# trng_reva register map
Registers are read-only, no defined reset value unless marked. A register's access mark holds for its fields unless they carry their own. Offsets are from the block's base; lines under a group give offsets from that group; [hi:lo] are bit positions; {n}, {i} and the like mark numbered series; 'fields as' and 'values as' point back to an identical list; <NAME> marks a mode.

## Memory map
0x400B5000 TRNG size 0x1000 — Random Number Generator.

## Interrupts
4 TRNG — TRNG interrupt.

## TRNG — Random Number Generator.
Base 0x400B5000
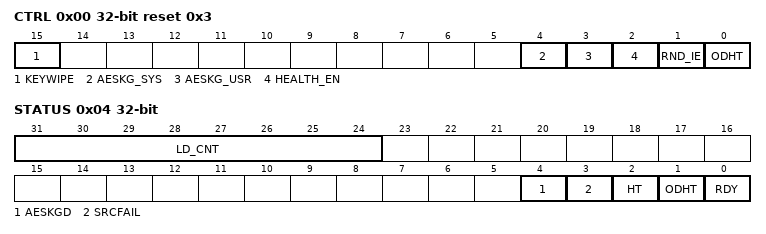
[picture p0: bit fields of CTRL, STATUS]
0x00 CTRL access not given reset 0x3 — TRNG Control Register.
  [15] KEYWIPE — Wipe Key.
  [4] AESKG_SYS — System block AES Key Gen.
  [3] AESKG_USR — User block AES Key Gen.
  [2] HEALTH_EN — Health Test Enable.
  [1] RND_IE — To enable IRQ generation when a new 32-bit Random number is ready.
  [0] ODHT — On Demand Health Test.
0x04 STATUS — Data. The content of this register is valid only when RNG_IS = 1. When TRNG is disabled, read returns 0x0000 0000.
  [31:24] LD_CNT — Load Count.
  [4] AESKGD — AES Key Gen Status.
  [3] SRCFAIL — Source Fail.
  [2] HT — Health test status.
  [1] ODHT — On demand health test.
  [0] RDY — 32-bit random data is ready to read from TRNG_DATA register. Reading TRNG_DATA when RND_RDY=0 will return all 0's. IRQ is generated when RND_RDY=1 if TRNG_CN.RND_IRQ_EN=1.
0x08 DATA — Data. The content of this register is valid only when RNG_IS = 1. When TRNG is disabled, read returns 0x0000 0000.
  [31:0] DATA — Data. The content of this register is valid only when RNG_IS =1. When TNRG is disabled, read returns 0x0000 0000.
